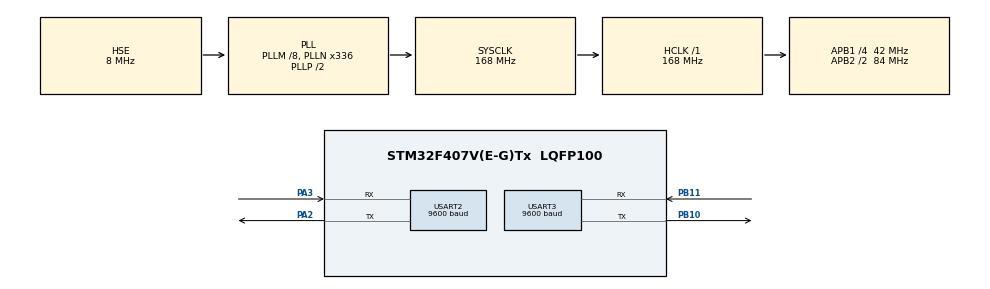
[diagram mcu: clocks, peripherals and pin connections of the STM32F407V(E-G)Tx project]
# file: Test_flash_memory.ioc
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Dma.Request0=USART3_RX
Dma.USART3_RX.0.Direction=DMA_PERIPH_TO_MEMORY
Dma.USART3_RX.0.FIFOMode=DMA_FIFOMODE_DISABLE
Dma.USART3_RX.0.Instance=DMA1_Stream1
Dma.USART3_RX.0.MemDataAlignment=DMA_MDATAALIGN_BYTE
Dma.USART3_RX.0.MemInc=DMA_MINC_ENABLE
Dma.USART3_RX.0.Mode=DMA_CIRCULAR
Dma.USART3_RX.0.PeriphDataAlignment=DMA_PDATAALIGN_BYTE
Dma.USART3_RX.0.PeriphInc=DMA_PINC_DISABLE
Dma.USART3_RX.0.Priority=DMA_PRIORITY_LOW
Mcu.Family=STM32F4
Mcu.Name=STM32F407V(E-G)Tx
Mcu.Package=LQFP100
NVIC.DMA1_Stream1_IRQn=true\:0\:0\:false\:false\:true\:false\:true
NVIC.PriorityGroup=NVIC_PRIORITYGROUP_0
PA13.Mode=Serial_Wire
PA13.Signal=SYS_JTMS-SWDIO
PA14.Mode=Serial_Wire
PA14.Signal=SYS_JTCK-SWCLK
PA2.Mode=Asynchronous
PA2.Signal=USART2_TX
PA3.Mode=Asynchronous
PA3.Signal=USART2_RX
PB10.Mode=Asynchronous
PB10.Signal=USART3_TX
PB11.Mode=Asynchronous
PB11.Signal=USART3_RX
PH0-OSC_IN.Mode=HSE-External-Oscillator
PH0-OSC_IN.Signal=RCC_OSC_IN
PH1-OSC_OUT.Mode=HSE-External-Oscillator
PH1-OSC_OUT.Signal=RCC_OSC_OUT
ProjectManager.HeapSize=0x200
ProjectManager.StackSize=0x400
ProjectManager.TargetToolchain=MDK-ARM V5
RCC.48MHZClocksFreq_Value=48000000
RCC.AHBFreq_Value=168000000
RCC.APB1CLKDivider=RCC_HCLK_DIV4
RCC.APB1Freq_Value=42000000
RCC.APB1TimFreq_Value=84000000
RCC.APB2CLKDivider=RCC_HCLK_DIV2
RCC.APB2Freq_Value=84000000
RCC.APB2TimFreq_Value=168000000
RCC.CortexFreq_Value=168000000
RCC.HCLKFreq_Value=168000000
RCC.HSE_VALUE=8000000
RCC.HSI_VALUE=16000000
RCC.PLLM=8
RCC.PLLN=336
RCC.PLLQ=7
RCC.PLLSourceVirtual=RCC_PLLSOURCE_HSE
RCC.SYSCLKFreq_VALUE=168000000
RCC.SYSCLKSource=RCC_SYSCLKSOURCE_PLLCLK
RCC.VCOOutputFreq_Value=336000000
USART2.BaudRate=9600
USART2.VirtualMode=VM_ASYNC
USART3.BaudRate=9600
USART3.VirtualMode=VM_ASYNC
board=STM32F407G-DISC1

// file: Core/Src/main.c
/* USER CODE BEGIN Header */
/**
  ******************************************************************************
  * @file           : main.c
  * @brief          : Main program body
  ******************************************************************************
  * @attention
  *
  * <h2><center>&copy; Copyright (c) 2021 STMicroelectronics.
  * All rights reserved.</center></h2>
  *
  * This software component is licensed by ST under BSD 3-Clause license,
  * the "License"; You may not use this file except in compliance with the
  * License. You may obtain a copy of the License at:
  *                        opensource.org/licenses/BSD-3-Clause
  *
  ******************************************************************************
  */
/* USER CODE END Header */
#include "main.h"
#include "my_flash.h"

UART_HandleTypeDef huart2;
UART_HandleTypeDef huart3;
DMA_HandleTypeDef hdma_usart3_rx;
uint8_t buffer[255];
/*$GPGLL,3751.65,S,14507.36,E*77
 $GPGLL,4916.45,N,12311.12,W,225444,A
*/
char* test_write [255]={"$GPGLL,3751.65,S,14507.36,E*77","$GPGLL,4916.45,N,12311.12,W,225444,A","$GPGLL,4916.45,N,12311.12,W,225444,A","$GPGLL,4916.45,N,12311.12,W,225444,A","$GPGLL,3751.65,S,14507.36,E*77","$GPGLL,3751.65,S,14507.36,E*77","$GPGLL,3751.65,S,14507.36,E*77",  };
char* test_read [255];

void SystemClock_Config(void);
static void MX_GPIO_Init(void);
static void MX_DMA_Init(void);
static void MX_USART2_UART_Init(void);
static void MX_USART3_UART_Init(void);

int main(void)
{

  /* MCU Configuration--------------------------------------------------------*/

  /* Reset of all peripherals, Initializes the Flash interface and the Systick. */
  HAL_Init();

  /* Configure the system clock */
  SystemClock_Config();

  /* Initialize all configured peripherals */
  MX_GPIO_Init();
  MX_DMA_Init();
  MX_USART2_UART_Init();
  MX_USART3_UART_Init();

  /* Infinite loop */
  /* USER CODE BEGIN WHILE */
	//HAL_UART_Receive_DMA(&huart3, buffer, 255);

	MY_FLASH_SetSectorAddrs(11,0x080E0000);
	MY_FLASH_WriteN(0,test_write,255,DATA_TYPE_8);
  while (1)

  {

		MY_FLASH_ReadN(0,test_read,255,DATA_TYPE_8);

		   HAL_Delay(1000);
     //HAL_UART_Transmit(&huart2, buffer, 255, 70);
     //HAL_UART_Transmit(&huart2, (uint8_t*) "\n", 1, 200);
     // HAL_UART_Transmit(&huart2,(uint8_t*)buffer, sizeof(buffer), 1000);
     // HAL_Delay(200);
    /* USER CODE END WHILE */

  }
}

void SystemClock_Config(void)
{
  RCC_OscInitTypeDef RCC_OscInitStruct = {0};
  RCC_ClkInitTypeDef RCC_ClkInitStruct = {0};

  /** Configure the main internal regulator output voltage
  */
  __HAL_RCC_PWR_CLK_ENABLE();
  __HAL_PWR_VOLTAGESCALING_CONFIG(PWR_REGULATOR_VOLTAGE_SCALE1);
  /** Initializes the RCC Oscillators according to the specified parameters
  * in the RCC_OscInitTypeDef structure.
  */
  RCC_OscInitStruct.OscillatorType = RCC_OSCILLATORTYPE_HSE;
  RCC_OscInitStruct.HSEState = RCC_HSE_ON;
  RCC_OscInitStruct.PLL.PLLState = RCC_PLL_ON;
  RCC_OscInitStruct.PLL.PLLSource = RCC_PLLSOURCE_HSE;
  RCC_OscInitStruct.PLL.PLLM = 8;
  RCC_OscInitStruct.PLL.PLLN = 336;
  RCC_OscInitStruct.PLL.PLLP = RCC_PLLP_DIV2;
  RCC_OscInitStruct.PLL.PLLQ = 7;
  if (HAL_RCC_OscConfig(&RCC_OscInitStruct) != HAL_OK)
  {
    Error_Handler();
  }
  /** Initializes the CPU, AHB and APB buses clocks
  */
  RCC_ClkInitStruct.ClockType = RCC_CLOCKTYPE_HCLK|RCC_CLOCKTYPE_SYSCLK
                              |RCC_CLOCKTYPE_PCLK1|RCC_CLOCKTYPE_PCLK2;
  RCC_ClkInitStruct.SYSCLKSource = RCC_SYSCLKSOURCE_PLLCLK;
  RCC_ClkInitStruct.AHBCLKDivider = RCC_SYSCLK_DIV1;
  RCC_ClkInitStruct.APB1CLKDivider = RCC_HCLK_DIV4;
  RCC_ClkInitStruct.APB2CLKDivider = RCC_HCLK_DIV2;

  if (HAL_RCC_ClockConfig(&RCC_ClkInitStruct, FLASH_LATENCY_5) != HAL_OK)
  {
    Error_Handler();
  }
}

static void MX_USART2_UART_Init(void)
{

  huart2.Instance = USART2;
  huart2.Init.BaudRate = 9600;
  huart2.Init.WordLength = UART_WORDLENGTH_8B;
  huart2.Init.StopBits = UART_STOPBITS_1;
  huart2.Init.Parity = UART_PARITY_NONE;
  huart2.Init.Mode = UART_MODE_TX_RX;
  huart2.Init.HwFlowCtl = UART_HWCONTROL_NONE;
  huart2.Init.OverSampling = UART_OVERSAMPLING_16;
  if (HAL_UART_Init(&huart2) != HAL_OK)
  {
    Error_Handler();
  }

}

static void MX_USART3_UART_Init(void)
{

  huart3.Instance = USART3;
  huart3.Init.BaudRate = 9600;
  huart3.Init.WordLength = UART_WORDLENGTH_8B;
  huart3.Init.StopBits = UART_STOPBITS_1;
  huart3.Init.Parity = UART_PARITY_NONE;
  huart3.Init.Mode = UART_MODE_TX_RX;
  huart3.Init.HwFlowCtl = UART_HWCONTROL_NONE;
  huart3.Init.OverSampling = UART_OVERSAMPLING_16;
  if (HAL_UART_Init(&huart3) != HAL_OK)
  {
    Error_Handler();
  }

}

static void MX_DMA_Init(void)
{

  /* DMA controller clock enable */
  __HAL_RCC_DMA1_CLK_ENABLE();

  /* DMA interrupt init */
  /* DMA1_Stream1_IRQn interrupt configuration */
  HAL_NVIC_SetPriority(DMA1_Stream1_IRQn, 0, 0);
  HAL_NVIC_EnableIRQ(DMA1_Stream1_IRQn);

}

static void MX_GPIO_Init(void)
{

  /* GPIO Ports Clock Enable */
  __HAL_RCC_GPIOH_CLK_ENABLE();
  __HAL_RCC_GPIOA_CLK_ENABLE();
  __HAL_RCC_GPIOB_CLK_ENABLE();

}

void Error_Handler(void)
{
  __disable_irq();
  while (1)
  {
  }
}

/************************ (C) COPYRIGHT STMicroelectronics *****END OF FILE****/
